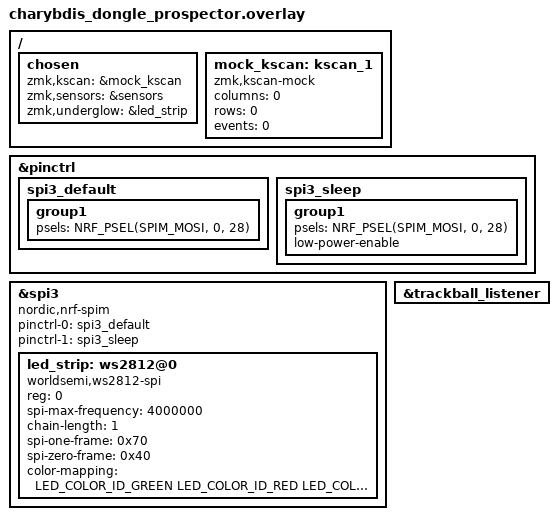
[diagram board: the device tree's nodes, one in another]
#include "charybdis.dtsi"
#include "charybdis_ec11.dtsi"
#include "split_input.dtsi"

/ {
    chosen {
        zmk,kscan = &mock_kscan;
        zmk,sensors = &sensors; // INFO: needed for the encoder
        zmk,underglow = &led_strip;
    };

    mock_kscan: kscan_1 {
        compatible = "zmk,kscan-mock";
        columns = <0>;
        rows = <0>;
        events = <0>;
    };
};

/*
 * RGB underglow stub for dongle - required for &rgb_ug behavior to work.
 * The dongle has no physical LEDs but needs the RGB subsystem active to
 * forward commands to peripherals. Uses SPI3 on an unused pin.
 * Note: Seeeduino XIAO BLE uses different pin numbering.
 */
#include <dt-bindings/led/led.h>
#include <dt-bindings/pinctrl/nrf-pinctrl.h>

&pinctrl {
    spi3_default: spi3_default {
        group1 {
            psels = <NRF_PSEL(SPIM_MOSI, 0, 28)>; /* D6 on XIAO BLE */
        };
    };
    spi3_sleep: spi3_sleep {
        group1 {
            psels = <NRF_PSEL(SPIM_MOSI, 0, 28)>;
            low-power-enable;
        };
    };
};

&spi3 {
    compatible = "nordic,nrf-spim";
    status = "okay";
    pinctrl-0 = <&spi3_default>;
    pinctrl-1 = <&spi3_sleep>;
    pinctrl-names = "default", "sleep";

    led_strip: ws2812@0 {
        compatible = "worldsemi,ws2812-spi";
        reg = <0>;
        spi-max-frequency = <4000000>;
        chain-length = <1>;
        spi-one-frame = <0x70>;
        spi-zero-frame = <0x40>;
        color-mapping = <LED_COLOR_ID_GREEN LED_COLOR_ID_RED LED_COLOR_ID_BLUE>;
    };
};

&trackball_listener {
    status = "okay";
};

// INFO: uncomment for dual trackball
// &trackball_left_listener {
//     status = "okay";
// };
